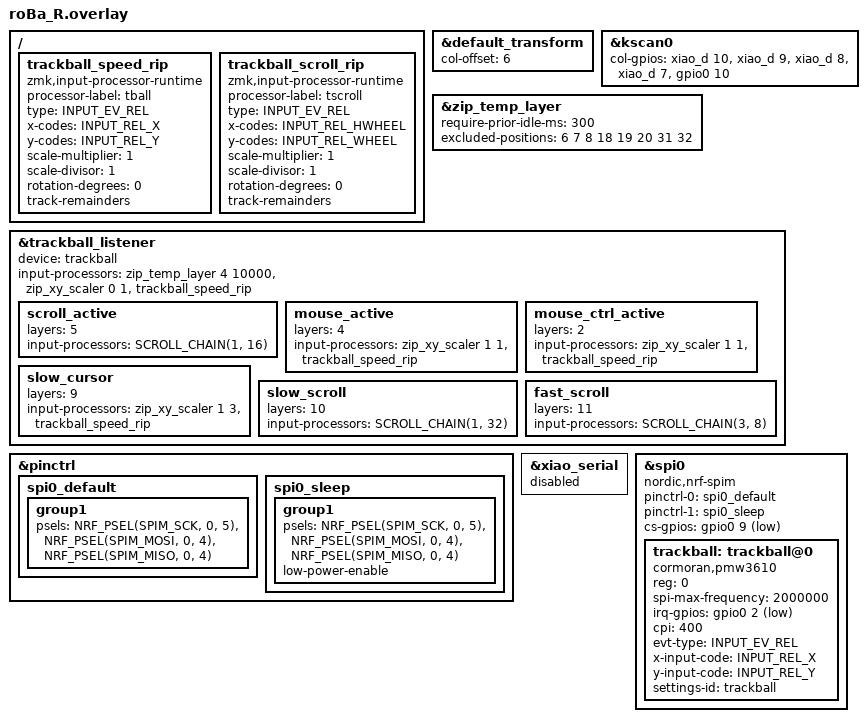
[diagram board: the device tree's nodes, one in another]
#include "roBa.dtsi"
#include <input/processors.dtsi>
#include <zephyr/dt-bindings/input/input-event-codes.h>
#include <dt-bindings/zmk/input_transform.h>

// ボールのXY移動をスクロールに変換する処理チェーン。ZMK 4系移行でドライバの
// scroll-layers が使えなくなったため、スクロール層ではprocessorで変換する。
// 旧ドライバ(SCROLL_TICK=16)の感度に合わせ 1/16 を標準とし、Y反転で自然なスクロール方向にする。
#define SCROLL_CHAIN(mul, div) \
    <&zip_xy_to_scroll_mapper>, \
    <&zip_scroll_transform INPUT_TRANSFORM_Y_INVERT>, \
    <&zip_scroll_scaler mul div>, \
    <&trackball_scroll_rip>

/ {
    // DYA Studio: カーソル速度のランタイム調整(既定1/1=補正なしで既存の挙動は不変)
    trackball_speed_rip: trackball_speed_rip {
        compatible = "zmk,input-processor-runtime";
        processor-label = "tball"; // 名前長制限(既定8文字)のため短縮
        type = <INPUT_EV_REL>;
        x-codes = <INPUT_REL_X>;
        y-codes = <INPUT_REL_Y>;
        scale-multiplier = <1>;
        scale-divisor = <1>;
        rotation-degrees = <0>;
        track-remainders;
        #input-processor-cells = <0>;
    };

    // DYA Studio: スクロール速度のランタイム調整(既定1/1=補正なし)
    trackball_scroll_rip: trackball_scroll_rip {
        compatible = "zmk,input-processor-runtime";
        processor-label = "tscroll";
        type = <INPUT_EV_REL>;
        x-codes = <INPUT_REL_HWHEEL>;
        y-codes = <INPUT_REL_WHEEL>;
        scale-multiplier = <1>;
        scale-divisor = <1>;
        rotation-degrees = <0>;
        track-remainders;
        #input-processor-cells = <0>;
    };
};

&default_transform {
    col-offset = <6>;
};

&kscan0 {
        col-gpios
            = <&xiao_d 10 GPIO_ACTIVE_HIGH>
            , <&xiao_d 9 GPIO_ACTIVE_HIGH> 
            , <&xiao_d 8 GPIO_ACTIVE_HIGH> 
            , <&xiao_d 7 GPIO_ACTIVE_HIGH> 
            , <&gpio0 10 GPIO_ACTIVE_HIGH>
            ;
};

// タイピング後 300ms 以内は AML を起動しない
// クリックボタンを押しても AML を維持する位置: MB4(6) MB3(7) MB5(8) LCLK(18,19,31) RCLK(20,32)
&zip_temp_layer {
    require-prior-idle-ms = <300>;
    excluded-positions = <6 7 8 18 19 20 31 32>;
};

&trackball_listener {
    status = "okay";
    device = <&trackball>;

    // ベース: MOUSE_L(4) を自動起動(10秒間有効) → 未起動時はカーソル移動を抑制
    input-processors = <&zip_temp_layer 4 10000>, <&zip_xy_scaler 0 1>, <&trackball_speed_rip>;

    // SCROLL_L(5) が有効なとき: ボール移動をスクロールに変換(標準速度)
    scroll_active {
        layers = <5>;
        input-processors = SCROLL_CHAIN(1, 16);
    };

    // MOUSE_L が有効なとき: 通常のカーソル移動を許可（ベースをスキップ）
    mouse_active {
        layers = <4>;
        input-processors = <&zip_xy_scaler 1 1>, <&trackball_speed_rip>;
    };

    // MOUSE_CTRL_L(2) が有効なとき: Spaceホールドでの使用のため移動を許可
    mouse_ctrl_active {
        layers = <2>;
        input-processors = <&zip_xy_scaler 1 1>, <&trackball_speed_rip>;
    };

    // SLOWTRACKBALL_L(9) が有効なとき: カーソル移動を低速化(標準の1/3。
    // torabo-tsuki-lpの標準比(1/6 ÷ 1/2 = 1/3)に合わせた比率)
    slow_cursor {
        layers = <9>;
        input-processors = <&zip_xy_scaler 1 3>, <&trackball_speed_rip>;
    };

    // SLOWSCROLL_L(10) が有効なとき: スクロールを低速化(標準の1/2。
    // torabo-tsuki-lpの標準比(1/8 ÷ 1/4 = 1/2)に合わせた比率)
    slow_scroll {
        layers = <10>;
        input-processors = SCROLL_CHAIN(1, 32);
    };

    // FASTRSCROLL_L(11) が有効なとき: スクロールを高速化(標準の6倍。
    // torabo-tsuki-lpの標準比(3/2 ÷ 1/4 = 6倍)に合わせた比率)
    fast_scroll {
        layers = <11>;
        input-processors = SCROLL_CHAIN(3, 8);
    };
};

&pinctrl {
    spi0_default: spi0_default {
        group1 {
            psels = <NRF_PSEL(SPIM_SCK, 0, 5)>,
                <NRF_PSEL(SPIM_MOSI, 0, 4)>,
                <NRF_PSEL(SPIM_MISO, 0, 4)>;
        };
    };

    spi0_sleep: spi0_sleep {
        group1 {
            psels = <NRF_PSEL(SPIM_SCK, 0, 5)>,
                <NRF_PSEL(SPIM_MOSI, 0, 4)>,
                <NRF_PSEL(SPIM_MISO, 0, 4)>;
            low-power-enable;
        };
    };
};

&xiao_serial { status = "disabled"; };

&spi0 {
    status = "okay";
    compatible = "nordic,nrf-spim";
    pinctrl-0 = <&spi0_default>;
    pinctrl-1 = <&spi0_sleep>;
    pinctrl-names = "default", "sleep";
    cs-gpios = <&gpio0 9 GPIO_ACTIVE_LOW>;

    trackball: trackball@0 {
        status = "okay";
        compatible = "cormoran,pmw3610";
        reg = <0>;
        spi-max-frequency = <2000000>;
        irq-gpios = <&gpio0 2 (GPIO_ACTIVE_LOW | GPIO_PULL_UP)>;
        cpi = <400>;
        evt-type = <INPUT_EV_REL>;
        x-input-code = <INPUT_REL_X>;
        y-input-code = <INPUT_REL_Y>;
        settings-id = "trackball";
    };
};
